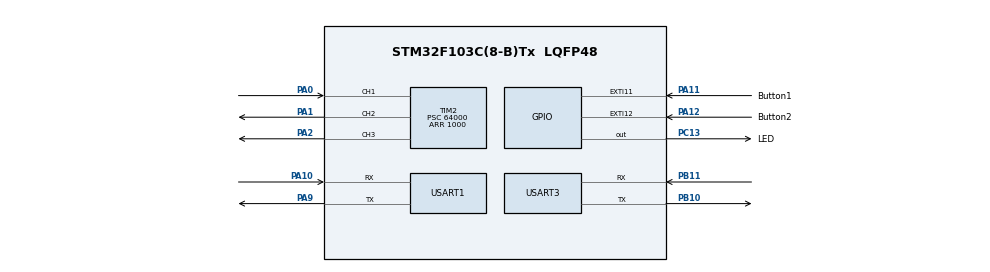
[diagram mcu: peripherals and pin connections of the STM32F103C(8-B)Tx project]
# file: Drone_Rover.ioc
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Dma.Request0=TIM2_CH1
Dma.Request1=TIM2_CH2/CH4
Dma.Request2=TIM2_CH3
Dma.TIM2_CH1.0.Direction=DMA_MEMORY_TO_PERIPH
Dma.TIM2_CH1.0.Instance=DMA1_Channel5
Dma.TIM2_CH1.0.MemDataAlignment=DMA_MDATAALIGN_HALFWORD
Dma.TIM2_CH1.0.MemInc=DMA_MINC_ENABLE
Dma.TIM2_CH1.0.Mode=DMA_NORMAL
Dma.TIM2_CH1.0.PeriphDataAlignment=DMA_PDATAALIGN_HALFWORD
Dma.TIM2_CH1.0.PeriphInc=DMA_PINC_DISABLE
Dma.TIM2_CH1.0.Priority=DMA_PRIORITY_LOW
Dma.TIM2_CH2/CH4.1.Direction=DMA_MEMORY_TO_PERIPH
Dma.TIM2_CH2/CH4.1.Instance=DMA1_Channel7
Dma.TIM2_CH2/CH4.1.MemDataAlignment=DMA_MDATAALIGN_HALFWORD
Dma.TIM2_CH2/CH4.1.MemInc=DMA_MINC_ENABLE
Dma.TIM2_CH2/CH4.1.Mode=DMA_NORMAL
Dma.TIM2_CH2/CH4.1.PeriphDataAlignment=DMA_PDATAALIGN_HALFWORD
Dma.TIM2_CH2/CH4.1.PeriphInc=DMA_PINC_DISABLE
Dma.TIM2_CH2/CH4.1.Priority=DMA_PRIORITY_LOW
Dma.TIM2_CH3.2.Direction=DMA_MEMORY_TO_PERIPH
Dma.TIM2_CH3.2.Instance=DMA1_Channel1
Dma.TIM2_CH3.2.MemDataAlignment=DMA_MDATAALIGN_HALFWORD
Dma.TIM2_CH3.2.MemInc=DMA_MINC_ENABLE
Dma.TIM2_CH3.2.Mode=DMA_NORMAL
Dma.TIM2_CH3.2.PeriphDataAlignment=DMA_PDATAALIGN_HALFWORD
Dma.TIM2_CH3.2.PeriphInc=DMA_PINC_DISABLE
Dma.TIM2_CH3.2.Priority=DMA_PRIORITY_LOW
FREERTOS.Queues01=myQueue01,16,uint16_t,0,Dynamic,NULL,NULL
FREERTOS.Tasks01=defaultTask,0,128,StartDefaultTask,Default,NULL,Dynamic,NULL,NULL
FREERTOS.configUSE_NEWLIB_REENTRANT=1
FREERTOS.configUSE_TIMERS=1
Mcu.Family=STM32F1
Mcu.Name=STM32F103C(8-B)Tx
Mcu.Package=LQFP48
NVIC.DMA1_Channel1_IRQn=true\:5\:0\:false\:false\:true\:true\:false\:true\:true
NVIC.DMA1_Channel5_IRQn=true\:5\:0\:false\:false\:true\:true\:false\:true\:true
NVIC.DMA1_Channel7_IRQn=true\:5\:0\:false\:false\:true\:true\:false\:true\:true
NVIC.PriorityGroup=NVIC_PRIORITYGROUP_4
NVIC.TIM1_UP_IRQn=true\:15\:0\:false\:false\:true\:false\:false\:true\:true
NVIC.TIM2_IRQn=true\:5\:0\:false\:false\:true\:true\:true\:true\:true
NVIC.TimeBase=TIM1_UP_IRQn
NVIC.TimeBaseIP=TIM1
PA0-WKUP.Signal=S_TIM2_CH1_ETR
PA1.Signal=S_TIM2_CH2
PA10.Mode=Asynchronous
PA10.Signal=USART1_RX
PA11.GPIO_Label=Button1
PA11.GPIO_ModeDefaultEXTI=GPIO_MODE_IT_RISING
PA11.Signal=GPXTI11
PA12.GPIO_Label=Button2
PA12.GPIO_ModeDefaultEXTI=GPIO_MODE_IT_RISING
PA12.Signal=GPXTI12
PA13.Mode=Serial_Wire
PA13.Signal=SYS_JTMS-SWDIO
PA14.Mode=Serial_Wire
PA14.Signal=SYS_JTCK-SWCLK
PA2.Signal=S_TIM2_CH3
PA9.Mode=Asynchronous
PA9.Signal=USART1_TX
PB10.Mode=Asynchronous
PB10.Signal=USART3_TX
PB11.Mode=Asynchronous
PB11.Signal=USART3_RX
PC13-TAMPER-RTC.GPIO_Label=LED
PC13-TAMPER-RTC.Signal=GPIO_Output
ProjectManager.HeapSize=0x200
ProjectManager.StackSize=0x400
ProjectManager.TargetToolchain=STM32CubeIDE
RCC.APB1Freq_Value=8000000
RCC.APB2Freq_Value=8000000
SH.S_TIM2_CH1_ETR.0=TIM2_CH1,Input_Capture1_from_TI1
SH.S_TIM2_CH2.0=TIM2_CH2,PWM Generation2 CH2
SH.S_TIM2_CH3.0=TIM2_CH3,PWM Generation3 CH3
TIM2.Channel-Input_Capture1_from_TI1=TIM_CHANNEL_1
TIM2.Channel-PWM\ Generation2\ CH2=TIM_CHANNEL_2
TIM2.Channel-PWM\ Generation3\ CH3=TIM_CHANNEL_3
TIM2.Period=1000
TIM2.Prescaler=64000
USART1.VirtualMode=VM_ASYNC
USART3.VirtualMode=VM_ASYNC
VP_FREERTOS_VS_CMSIS_V1.Mode=CMSIS_V1
VP_SYS_VS_tim1.Mode=TIM1
VP_TIM2_VS_ClockSourceINT.Mode=Internal
board=custom

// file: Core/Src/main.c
/* USER CODE BEGIN Header */
/**
  ******************************************************************************
  * @file           : main.c
  * @brief          : Main program body
  ******************************************************************************
  * @attention
  *
  * Copyright (c) 2025 STMicroelectronics.
  * All rights reserved.
  *
  * This software is licensed under terms that can be found in the LICENSE file
  * in the root directory of this software component.
  * If no LICENSE file comes with this software, it is provided AS-IS.
  *
  ******************************************************************************
  */
/* USER CODE END Header */
#include "main.h"
#include "cmsis_os.h"

TIM_HandleTypeDef htim2;
DMA_HandleTypeDef hdma_tim2_ch1;
DMA_HandleTypeDef hdma_tim2_ch2_ch4;
DMA_HandleTypeDef hdma_tim2_ch3;

UART_HandleTypeDef huart1;
UART_HandleTypeDef huart3;

osThreadId defaultTaskHandle;
osMessageQId myQueue01Handle;

void SystemClock_Config(void);
static void MX_GPIO_Init(void);
static void MX_DMA_Init(void);
static void MX_TIM2_Init(void);
static void MX_USART1_UART_Init(void);
static void MX_USART3_UART_Init(void);
void StartDefaultTask(void const * argument);

int main(void)
{

  /* MCU Configuration--------------------------------------------------------*/

  /* Reset of all peripherals, Initializes the Flash interface and the Systick. */
  HAL_Init();

  /* Configure the system clock */
  SystemClock_Config();

  /* Initialize all configured peripherals */
  MX_GPIO_Init();
  MX_DMA_Init();
  MX_TIM2_Init();
  MX_USART1_UART_Init();
  MX_USART3_UART_Init();

  /* Create the queue(s) */
  /* definition and creation of myQueue01 */
  osMessageQDef(myQueue01, 16, uint16_t);
  myQueue01Handle = osMessageCreate(osMessageQ(myQueue01), NULL);

  /* Create the thread(s) */
  /* definition and creation of defaultTask */
  osThreadDef(defaultTask, StartDefaultTask, osPriorityNormal, 0, 128);
  defaultTaskHandle = osThreadCreate(osThread(defaultTask), NULL);

  /* Start scheduler */
  osKernelStart();

  /* We should never get here as control is now taken by the scheduler */

  /* Infinite loop */
  while (1)
  {

  }
}

void SystemClock_Config(void)
{
  RCC_OscInitTypeDef RCC_OscInitStruct = {0};
  RCC_ClkInitTypeDef RCC_ClkInitStruct = {0};

  /** Initializes the RCC Oscillators according to the specified parameters
  * in the RCC_OscInitTypeDef structure.
  */
  RCC_OscInitStruct.OscillatorType = RCC_OSCILLATORTYPE_HSI;
  RCC_OscInitStruct.HSIState = RCC_HSI_ON;
  RCC_OscInitStruct.HSICalibrationValue = RCC_HSICALIBRATION_DEFAULT;
  RCC_OscInitStruct.PLL.PLLState = RCC_PLL_NONE;
  if (HAL_RCC_OscConfig(&RCC_OscInitStruct) != HAL_OK)
  {
    Error_Handler();
  }

  /** Initializes the CPU, AHB and APB buses clocks
  */
  RCC_ClkInitStruct.ClockType = RCC_CLOCKTYPE_HCLK|RCC_CLOCKTYPE_SYSCLK
                              |RCC_CLOCKTYPE_PCLK1|RCC_CLOCKTYPE_PCLK2;
  RCC_ClkInitStruct.SYSCLKSource = RCC_SYSCLKSOURCE_HSI;
  RCC_ClkInitStruct.AHBCLKDivider = RCC_SYSCLK_DIV1;
  RCC_ClkInitStruct.APB1CLKDivider = RCC_HCLK_DIV1;
  RCC_ClkInitStruct.APB2CLKDivider = RCC_HCLK_DIV1;

  if (HAL_RCC_ClockConfig(&RCC_ClkInitStruct, FLASH_LATENCY_0) != HAL_OK)
  {
    Error_Handler();
  }
}

static void MX_TIM2_Init(void)
{

  TIM_ClockConfigTypeDef sClockSourceConfig = {0};
  TIM_MasterConfigTypeDef sMasterConfig = {0};
  TIM_IC_InitTypeDef sConfigIC = {0};
  TIM_OC_InitTypeDef sConfigOC = {0};

  htim2.Instance = TIM2;
  htim2.Init.Prescaler = 64000;
  htim2.Init.CounterMode = TIM_COUNTERMODE_UP;
  htim2.Init.Period = 1000;
  htim2.Init.ClockDivision = TIM_CLOCKDIVISION_DIV1;
  htim2.Init.AutoReloadPreload = TIM_AUTORELOAD_PRELOAD_DISABLE;
  if (HAL_TIM_Base_Init(&htim2) != HAL_OK)
  {
    Error_Handler();
  }
  sClockSourceConfig.ClockSource = TIM_CLOCKSOURCE_INTERNAL;
  if (HAL_TIM_ConfigClockSource(&htim2, &sClockSourceConfig) != HAL_OK)
  {
    Error_Handler();
  }
  if (HAL_TIM_IC_Init(&htim2) != HAL_OK)
  {
    Error_Handler();
  }
  if (HAL_TIM_PWM_Init(&htim2) != HAL_OK)
  {
    Error_Handler();
  }
  sMasterConfig.MasterOutputTrigger = TIM_TRGO_RESET;
  sMasterConfig.MasterSlaveMode = TIM_MASTERSLAVEMODE_DISABLE;
  if (HAL_TIMEx_MasterConfigSynchronization(&htim2, &sMasterConfig) != HAL_OK)
  {
    Error_Handler();
  }
  sConfigIC.ICPolarity = TIM_INPUTCHANNELPOLARITY_RISING;
  sConfigIC.ICSelection = TIM_ICSELECTION_DIRECTTI;
  sConfigIC.ICPrescaler = TIM_ICPSC_DIV1;
  sConfigIC.ICFilter = 0;
  if (HAL_TIM_IC_ConfigChannel(&htim2, &sConfigIC, TIM_CHANNEL_1) != HAL_OK)
  {
    Error_Handler();
  }
  sConfigOC.OCMode = TIM_OCMODE_PWM1;
  sConfigOC.Pulse = 0;
  sConfigOC.OCPolarity = TIM_OCPOLARITY_HIGH;
  sConfigOC.OCFastMode = TIM_OCFAST_DISABLE;
  if (HAL_TIM_PWM_ConfigChannel(&htim2, &sConfigOC, TIM_CHANNEL_2) != HAL_OK)
  {
    Error_Handler();
  }
  if (HAL_TIM_PWM_ConfigChannel(&htim2, &sConfigOC, TIM_CHANNEL_3) != HAL_OK)
  {
    Error_Handler();
  }
  HAL_TIM_MspPostInit(&htim2);

}

static void MX_USART1_UART_Init(void)
{

  huart1.Instance = USART1;
  huart1.Init.BaudRate = 115200;
  huart1.Init.WordLength = UART_WORDLENGTH_8B;
  huart1.Init.StopBits = UART_STOPBITS_1;
  huart1.Init.Parity = UART_PARITY_NONE;
  huart1.Init.Mode = UART_MODE_TX_RX;
  huart1.Init.HwFlowCtl = UART_HWCONTROL_NONE;
  huart1.Init.OverSampling = UART_OVERSAMPLING_16;
  if (HAL_UART_Init(&huart1) != HAL_OK)
  {
    Error_Handler();
  }

}

static void MX_USART3_UART_Init(void)
{

  huart3.Instance = USART3;
  huart3.Init.BaudRate = 115200;
  huart3.Init.WordLength = UART_WORDLENGTH_8B;
  huart3.Init.StopBits = UART_STOPBITS_1;
  huart3.Init.Parity = UART_PARITY_NONE;
  huart3.Init.Mode = UART_MODE_TX_RX;
  huart3.Init.HwFlowCtl = UART_HWCONTROL_NONE;
  huart3.Init.OverSampling = UART_OVERSAMPLING_16;
  if (HAL_UART_Init(&huart3) != HAL_OK)
  {
    Error_Handler();
  }

}

static void MX_DMA_Init(void)
{

  /* DMA controller clock enable */
  __HAL_RCC_DMA1_CLK_ENABLE();

  /* DMA interrupt init */
  /* DMA1_Channel1_IRQn interrupt configuration */
  HAL_NVIC_SetPriority(DMA1_Channel1_IRQn, 5, 0);
  HAL_NVIC_EnableIRQ(DMA1_Channel1_IRQn);
  /* DMA1_Channel5_IRQn interrupt configuration */
  HAL_NVIC_SetPriority(DMA1_Channel5_IRQn, 5, 0);
  HAL_NVIC_EnableIRQ(DMA1_Channel5_IRQn);
  /* DMA1_Channel7_IRQn interrupt configuration */
  HAL_NVIC_SetPriority(DMA1_Channel7_IRQn, 5, 0);
  HAL_NVIC_EnableIRQ(DMA1_Channel7_IRQn);

}

static void MX_GPIO_Init(void)
{
  GPIO_InitTypeDef GPIO_InitStruct = {0};

  /* GPIO Ports Clock Enable */
  __HAL_RCC_GPIOC_CLK_ENABLE();
  __HAL_RCC_GPIOA_CLK_ENABLE();
  __HAL_RCC_GPIOB_CLK_ENABLE();

  /*Configure GPIO pin Output Level */
  HAL_GPIO_WritePin(LED_GPIO_Port, LED_Pin, GPIO_PIN_RESET);

  /*Configure GPIO pin : LED_Pin */
  GPIO_InitStruct.Pin = LED_Pin;
  GPIO_InitStruct.Mode = GPIO_MODE_OUTPUT_PP;
  GPIO_InitStruct.Pull = GPIO_NOPULL;
  GPIO_InitStruct.Speed = GPIO_SPEED_FREQ_LOW;
  HAL_GPIO_Init(LED_GPIO_Port, &GPIO_InitStruct);

  /*Configure GPIO pins : Button1_Pin Button2_Pin */
  GPIO_InitStruct.Pin = Button1_Pin|Button2_Pin;
  GPIO_InitStruct.Mode = GPIO_MODE_IT_RISING;
  GPIO_InitStruct.Pull = GPIO_NOPULL;
  HAL_GPIO_Init(GPIOA, &GPIO_InitStruct);

}

void StartDefaultTask(void const * argument)
{
  /* USER CODE BEGIN 5 */
  /* Infinite loop */
  for(;;)
  {
    osDelay(osWaitForever);
  }
  /* USER CODE END 5 */
}

void HAL_TIM_PeriodElapsedCallback(TIM_HandleTypeDef *htim)
{
  if (htim->Instance == TIM1)
  {
    HAL_IncTick();
  }
}

void Error_Handler(void)
{
  __disable_irq();
  while (1)
  {
  }
}
